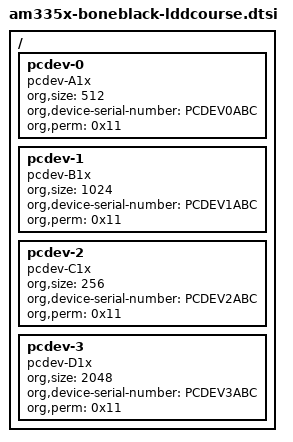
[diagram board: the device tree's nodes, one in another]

/ {
	pcdev-0 {
		compatible = "pcdev-A1x";
		org,size = <512>;
		org,device-serial-number = "PCDEV0ABC";
		org,perm = <0x11>;
	};
	pcdev-1 {
		compatible = "pcdev-B1x";
		org,size = <1024>;
		org,device-serial-number = "PCDEV1ABC";
		org,perm = <0x11>;
	};
	pcdev-2 {
		compatible = "pcdev-C1x";
		org,size = <256>;
		org,device-serial-number = "PCDEV2ABC";
		org,perm = <0x11>;
	};
	pcdev-3 {
		compatible = "pcdev-D1x";
		org,size = <2048>;
		org,device-serial-number = "PCDEV3ABC";
		org,perm = <0x11>;
	};
};
